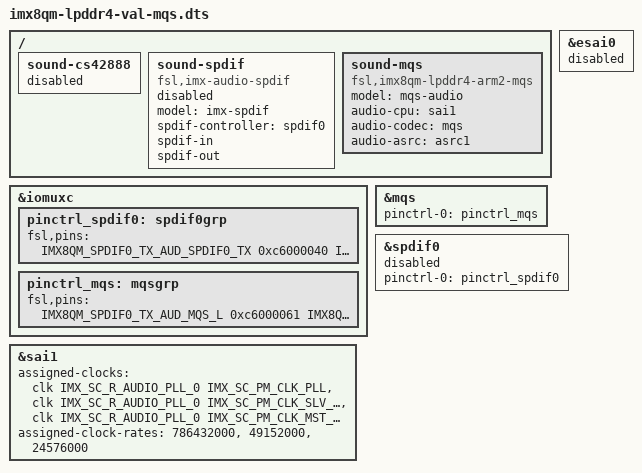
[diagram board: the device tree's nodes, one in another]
/*
 * Copyright 2017 NXP
 *
 * This program is free software; you can redistribute it and/or
 * modify it under the terms of the GNU General Public License
 * as published by the Free Software Foundation; either version 2
 * of the License, or (at your option) any later version.
 *
 * This program is distributed in the hope that it will be useful,
 * but WITHOUT ANY WARRANTY; without even the implied warranty of
 * MERCHANTABILITY or FITNESS FOR A PARTICULAR PURPOSE.  See the
 * GNU General Public License for more details.
 */

#include "imx8qm-lpddr4-val.dts"

/ {
	sound-cs42888 {
		status = "disabled";
	};

	sound-spdif {
		compatible = "fsl,imx-audio-spdif";
		model = "imx-spdif";
		spdif-controller = <&spdif0>;
		spdif-in;
		spdif-out;
		status = "disabled";
	};

	sound-mqs {
		compatible = "fsl,imx8qm-lpddr4-arm2-mqs",
				"fsl,imx-audio-mqs";
		model = "mqs-audio";
		audio-cpu = <&sai1>;
		audio-codec = <&mqs>;
		audio-asrc = <&asrc1>;
	};
};

&esai0 {
	status = "disabled";
};

&iomuxc {
	pinctrl_spdif0: spdif0grp {
		fsl,pins = <
			IMX8QM_SPDIF0_TX_AUD_SPDIF0_TX	0xc6000040
			IMX8QM_SPDIF0_RX_AUD_SPDIF0_RX	0xc6000040
		>;
	};

	pinctrl_mqs: mqsgrp {
		fsl,pins = <
			IMX8QM_SPDIF0_TX_AUD_MQS_L	0xc6000061
			IMX8QM_SPDIF0_RX_AUD_MQS_R	0xc6000061
		>;
	};
};

&mqs {
	pinctrl-names = "default";
	pinctrl-0 = <&pinctrl_mqs>;
	status = "okay";
};

&spdif0 {
	pinctrl-names = "default";
	pinctrl-0 = <&pinctrl_spdif0>;
	status = "disabled";
};

&sai1 {
	assigned-clocks = <&clk IMX_SC_R_AUDIO_PLL_0 IMX_SC_PM_CLK_PLL>,
			<&clk IMX_SC_R_AUDIO_PLL_0 IMX_SC_PM_CLK_SLV_BUS>,
			<&clk IMX_SC_R_AUDIO_PLL_0 IMX_SC_PM_CLK_MST_BUS>;
	assigned-clock-rates = <786432000>, <49152000>, <24576000>;
	status = "okay";
};
